# RP2350 register map
Vendor: Raspberry Pi; File version: 0.1
CPU: CM33 r1p0, little endian, MPU, FPU, VTOR, 4 interrupt priority bits, 54 interrupts, 8 SAU regions
Registers are 32-bit, read-write, reset 0x0 unless marked. A register's access mark holds for its fields unless they carry their own. Offsets are from the block's base; [hi:lo] are bit positions; 'fields as' and 'values as' point back to an identical list.

## XIP_QMI — QSPI Memory Interface. . Provides a memory-mapped interface to up to two SPI/DSPI/QSPI flash or PSRAM devices. Also provides a serial interface for programming and configuration of the external device.
Base 0x400D0000
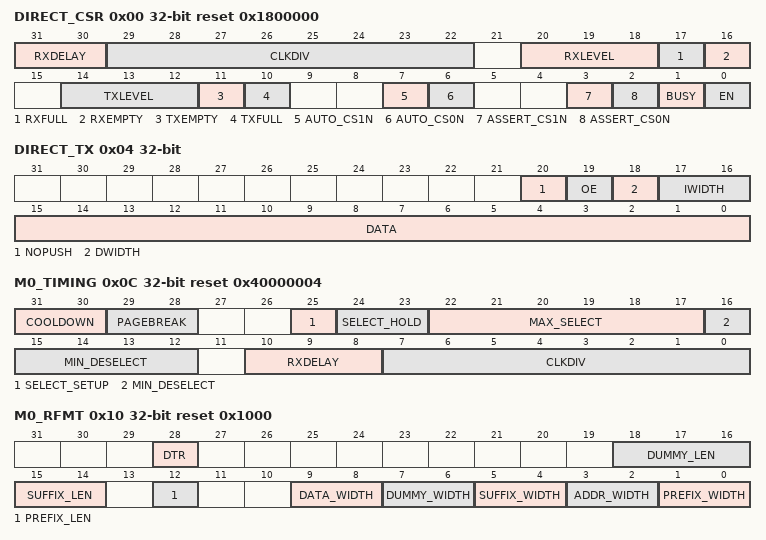
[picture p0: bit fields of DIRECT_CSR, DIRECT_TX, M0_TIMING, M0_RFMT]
0x00 DIRECT_CSR access per field reset 0x1800000 — Control and status for direct serial mode . Direct serial mode allows the processor to send and receive raw serial frames, for programming, configuration and control of the external memory devices. Only SPI mode 0 (CPOL=0 CPHA=0) is supported.
  [31:30] RXDELAY rw — Delay the read data sample timing, in units of one half of a system clock cycle. (Not necessarily half of an SCK cycle.)
  [29:22] CLKDIV rw — Clock divisor for direct serial mode. Divisors of 1..255 are encoded directly, and the maximum divisor of 256 is encoded by a value of CLKDIV=0. . The clock divisor can be changed on-the-fly by software, without halting or otherwise coordinating with the serial interface. The serial interface will sample the latest clock divisor each time it begins the transmission of a new byte.
  [20:18] RXLEVEL ro — Current level of DIRECT_RX FIFO
  [17] RXFULL ro — When 1, the DIRECT_RX FIFO is currently full. The serial interface will be stalled until data is popped; the interface will not begin a new serial frame when the DIRECT_TX FIFO is empty or the DIRECT_RX FIFO is full.
  [16] RXEMPTY ro — When 1, the DIRECT_RX FIFO is currently empty. If the processor attempts to read more data, the FIFO state is not affected, but the value returned to the processor is undefined.
  [14:12] TXLEVEL ro — Current level of DIRECT_TX FIFO
  [11] TXEMPTY ro — When 1, the DIRECT_TX FIFO is currently empty. Unless the processor pushes more data, transmission will stop and BUSY will go low once the current 8-bit serial frame completes.
  [10] TXFULL ro — When 1, the DIRECT_TX FIFO is currently full. If the processor tries to write more data, that data will be ignored.
  [7] AUTO_CS1N rw — When 1, automatically assert the CS1n chip select line whenever the BUSY flag is set.
  [6] AUTO_CS0N rw — When 1, automatically assert the CS0n chip select line whenever the BUSY flag is set.
  [3] ASSERT_CS1N rw — When 1, assert (i.e. drive low) the CS1n chip select line. . Note that this applies even when DIRECT_CSR_EN is 0.
  [2] ASSERT_CS0N rw — When 1, assert (i.e. drive low) the CS0n chip select line. . Note that this applies even when DIRECT_CSR_EN is 0.
  [1] BUSY ro — Direct mode busy flag. If 1, data is currently being shifted in/out (or would be if the interface were not stalled on the RX FIFO), and the chip select must not yet be deasserted. . The busy flag will also be set to 1 if a memory-mapped transfer is still in progress when direct mode is enabled. Direct mode blocks new memory-mapped transfers, but can't halt a transfer that is already in progress. If there is a chance that memory-mapped transfers may be in progress, the busy flag should be polled for 0 before asserting the chip select. (In practice you will usually discover this timing condition through other means, because any subsequent memory-mapped transfers when direct mode is enabled will return bus errors, which are difficult to ignore.)
  [0] EN rw — Enable direct mode. . In direct mode, software controls the chip select lines, and can perform direct SPI transfers by pushing data to the DIRECT_TX FIFO, and popping the same amount of data from the DIRECT_RX FIFO. . Memory-mapped accesses will generate bus errors when direct serial mode is enabled.
0x04 DIRECT_TX wo — Transmit FIFO for direct mode
  [20] NOPUSH read-has-side-effects — Inhibit the RX FIFO push that would correspond to this TX FIFO entry. . Useful to avoid garbage appearing in the RX FIFO when pushing the command at the beginning of a SPI transfer.
  [19] OE read-has-side-effects — Output enable (active-high). For single width (SPI), this field is ignored, and SD0 is always set to output, with SD1 always set to input. . For dual and quad width (DSPI/QSPI), this sets whether the relevant SDx pads are set to output whilst transferring this FIFO record. In this case the command/address should have OE set, and the data transfer should have OE set or clear depending on the direction of the transfer.
  [18] DWIDTH read-has-side-effects — Data width. If 0, hardware will transmit the 8 LSBs of the DIRECT_TX DATA field, and return an 8-bit value in the 8 LSBs of DIRECT_RX. If 1, the full 16-bit width is used. 8-bit and 16-bit transfers can be mixed freely.
  [17:16] IWIDTH read-has-side-effects — Configure whether this FIFO record is transferred with single/dual/quad interface width (0/1/2). Different widths can be mixed freely.
    0=S (Single width); 1=D (Dual width); 2=Q (Quad width)
  [15:0] DATA read-has-side-effects — Data pushed here will be clocked out falling edges of SCK (or before the very first rising edge of SCK, if this is the first pulse). For each byte clocked out, the interface will simultaneously sample one byte, on rising edges of SCK, and push this to the DIRECT_RX FIFO. . For 16-bit data, the least-significant byte is transmitted first.
0x08 DIRECT_RX ro — Receive FIFO for direct mode
  [15:0] DIRECT_RX read-has-side-effects — With each byte clocked out on the serial interface, one byte will simultaneously be clocked in, and will appear in this FIFO. The serial interface will stall when this FIFO is full, to avoid dropping data. . When 16-bit data is pushed into the TX FIFO, the corresponding RX FIFO push will also contain 16 bits of data. The least-significant byte is the first one received.
0x0C M0_TIMING reset 0x40000004 — Timing configuration register for memory address window 0.
  [31:30] COOLDOWN — Chip select cooldown period. When a memory transfer finishes, the chip select remains asserted for 64 x COOLDOWN system clock cycles, plus half an SCK clock period (rounded up for odd SCK divisors). After this cooldown expires, the chip select is always deasserted to save power. . If the next memory access arrives within the cooldown period, the QMI may be able to append more SCK cycles to the currently ongoing SPI transfer, rather than starting a new transfer. This reduces access latency and increases bus throughput. . Specifically, the next access must be in the same direction (read/write), access the same memory window (chip select 0/1), and follow sequentially the address of the last transfer. If any of these are false, the new access will first deassert the chip select, then begin a new transfer. . If COOLDOWN is 0, the address alignment configured by PAGEBREAK has been reached, or the total chip select assertion limit MAX_SELECT has been reached, the cooldown period is skipped, and the chip select will always be deasserted one half SCK period after the transfer finishes.
  [29:28] PAGEBREAK — When page break is enabled, chip select will automatically deassert when crossing certain power-of-2-aligned address boundaries. The next access will always begin a new read/write SPI burst, even if the address of the next access follows in sequence with the last access before the page boundary. . Some flash and PSRAM devices forbid crossing page boundaries with a single read/write transfer, or restrict the operating frequency for transfers that do cross page a boundary. This option allows the QMI to safely support those devices. . This field has no effect when COOLDOWN is disabled.
    0=NONE (No page boundary is enforced); 1=Break bursts crossing a 256-byte page boundary; 2=Break bursts crossing a 1024-byte quad-page boundary; 3=Break bursts crossing a 4096-byte sector boundary
  [25] SELECT_SETUP — Add up to one additional system clock cycle of setup between chip select assertion and the first rising edge of SCK. . The default setup time is one half SCK period, which is usually sufficient except for very high SCK frequencies with some flash devices.
  [24:23] SELECT_HOLD — Add up to three additional system clock cycles of active hold between the last falling edge of SCK and the deassertion of this window's chip select. . The default hold time is one system clock cycle. Note that flash datasheets usually give chip select active hold time from the last *rising* edge of SCK, and so even zero hold from the last falling edge would be safe. . Note that this is a minimum hold time guaranteed by the QMI: the actual chip select active hold may be slightly longer for read transfers with low clock divisors and/or high sample delays. Specifically, if the point two cycles after the last RX data sample is later than the last SCK falling edge, then the hold time is measured from *this* point. . Note also that, in case the final SCK pulse is masked to save energy (true for non-DTR reads when COOLDOWN is disabled or PAGE_BREAK is reached), all of QMI's timing logic behaves as though the clock pulse were still present. The SELECT_HOLD time is applied from the point where the last SCK falling edge would be if the clock pulse were not masked.
  [22:17] MAX_SELECT — Enforce a maximum assertion duration for this window's chip select, in units of 64 system clock cycles. If 0, the QMI is permitted to keep the chip select asserted indefinitely when servicing sequential memory accesses (see COOLDOWN). . This feature is required to meet timing constraints of PSRAM devices, which specify a maximum chip select assertion so they can perform DRAM refresh cycles. See also MIN_DESELECT, which can enforce a minimum deselect time. . If a memory access is in progress at the time MAX_SELECT is reached, the QMI will wait for the access to complete before deasserting the chip select. This additional time must be accounted for to calculate a safe MAX_SELECT value. In the worst case, this may be a fully-formed serial transfer, including command prefix and address, with a data payload as large as one cache line.
  [16:12] MIN_DESELECT — After this window's chip select is deasserted, it remains deasserted for half an SCK cycle (rounded up to an integer number of system clock cycles), plus MIN_DESELECT additional system clock cycles, before the QMI reasserts either chip select pin. . Nonzero values may be required for PSRAM devices which enforce a longer minimum CS deselect time, so that they can perform internal DRAM refresh cycles whilst deselected.
  [10:8] RXDELAY — Delay the read data sample timing, in units of one half of a system clock cycle. (Not necessarily half of an SCK cycle.) An RXDELAY of 0 means the sample is captured at the SDI input registers simultaneously with the rising edge of SCK launched from the SCK output register. . At higher SCK frequencies, RXDELAY may need to be increased to account for the round trip delay of the pads, and the clock-to-Q delay of the QSPI memory device.
  [7:0] CLKDIV — Clock divisor. Odd and even divisors are supported. Defines the SCK clock period in units of 1 system clock cycle. Divisors 1..255 are encoded directly, and a divisor of 256 is encoded with a value of CLKDIV=0. . The clock divisor can be changed on-the-fly, even when the QMI is currently accessing memory in this address window. All other parameters must only be changed when the QMI is idle. . If software is increasing CLKDIV in anticipation of an increase in the system clock frequency, a dummy access to either memory window (and appropriate processor barriers/fences) must be inserted after the Mx_TIMING write to ensure the SCK divisor change is in effect _before_ the system clock is changed.
0x10 M0_RFMT reset 0x1000 — Read transfer format configuration for memory address window 0. . Configure the bus width of each transfer phase individually, and configure the length or presence of the command prefix, command suffix and dummy/turnaround transfer phases. Only 24-bit addresses are supported. . The reset value of the M0_RFMT register is configured to support a basic 03h serial read transfer with no additional configuration.
  [28] DTR — Enable double transfer rate (DTR) for read commands: address, suffix and read data phases are active on both edges of SCK. SDO data is launched centre-aligned on each SCK edge, and SDI data is captured on the SCK edge that follows its launch. . DTR is implemented by halving the clock rate; SCK has a period of 2 x CLK_DIV throughout the transfer. The prefix and dummy phases are still single transfer rate. . If the suffix is quad-width, it must be 0 or 8 bits in length, to ensure an even number of SCK edges.
  [18:16] DUMMY_LEN — Length of dummy phase between command suffix and data phase, in units of 4 bits. (i.e. 1 cycle for quad width, 2 for dual, 4 for single)
    0=NONE (No dummy phase); 1=4 dummy bits; 2=8 dummy bits; 3=12 dummy bits; 4=16 dummy bits; 5=20 dummy bits; 6=24 dummy bits; 7=28 dummy bits
  [15:14] SUFFIX_LEN — Length of post-address command suffix, in units of 4 bits. (i.e. 1 cycle for quad width, 2 for dual, 4 for single) . Only values of 0 and 8 bits are supported.
    0=NONE (No suffix); 2=8-bit suffix
  [12] PREFIX_LEN — Length of command prefix, in units of 8 bits. (i.e. 2 cycles for quad width, 4 for dual, 8 for single)
    0=NONE (No prefix); 1=8-bit prefix
  [9:8] DATA_WIDTH — The width used for the data transfer
    0=S (Single width); 1=D (Dual width); 2=Q (Quad width)
  [7:6] DUMMY_WIDTH — The width used for the dummy phase, if any. . If width is single, SD0/MOSI is held asserted low during the dummy phase, and SD1...SD3 are tristated. If width is dual/quad, all IOs are tristated during the dummy phase.
    0=S (Single width); 1=D (Dual width); 2=Q (Quad width)
  [5:4] SUFFIX_WIDTH — The width used for the post-address command suffix, if any
    0=S (Single width); 1=D (Dual width); 2=Q (Quad width)
  [3:2] ADDR_WIDTH — The transfer width used for the address. The address phase always transfers 24 bits in total.
    0=S (Single width); 1=D (Dual width); 2=Q (Quad width)
  [1:0] PREFIX_WIDTH — The transfer width used for the command prefix, if any
    0=S (Single width); 1=D (Dual width); 2=Q (Quad width)
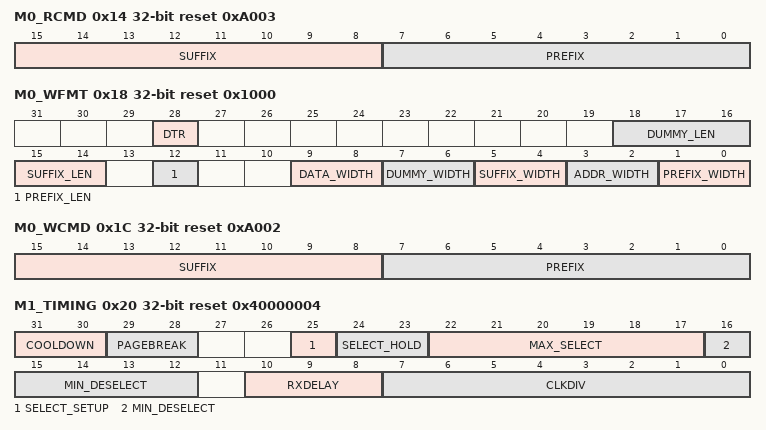
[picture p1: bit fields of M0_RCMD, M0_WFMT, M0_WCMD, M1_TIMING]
0x14 M0_RCMD reset 0xA003 — Command constants used for reads from memory address window 0. . The reset value of the M0_RCMD register is configured to support a basic 03h serial read transfer with no additional configuration.
  [15:8] SUFFIX — The command suffix bits following the address, if Mx_RFMT_SUFFIX_LEN is nonzero.
  [7:0] PREFIX — The command prefix bits to prepend on each new transfer, if Mx_RFMT_PREFIX_LEN is nonzero.
0x18 M0_WFMT reset 0x1000 — Write transfer format configuration for memory address window 0. . Configure the bus width of each transfer phase individually, and configure the length or presence of the command prefix, command suffix and dummy/turnaround transfer phases. Only 24-bit addresses are supported. . The reset value of the M0_WFMT register is configured to support a basic 02h serial write transfer. However, writes to this window must first be enabled via the XIP_CTRL_WRITABLE_M0 bit, as XIP memory is read-only by default.
  [28] DTR — Enable double transfer rate (DTR) for write commands: address, suffix and write data phases are active on both edges of SCK. SDO data is launched centre-aligned on each SCK edge, and SDI data is captured on the SCK edge that follows its launch. . DTR is implemented by halving the clock rate; SCK has a period of 2 x CLK_DIV throughout the transfer. The prefix and dummy phases are still single transfer rate. . If the suffix is quad-width, it must be 0 or 8 bits in length, to ensure an even number of SCK edges.
  [18:16] DUMMY_LEN — Length of dummy phase between command suffix and data phase, in units of 4 bits. (i.e. 1 cycle for quad width, 2 for dual, 4 for single)
    values as M0_RFMT.DUMMY_LEN
  [15:14] SUFFIX_LEN — Length of post-address command suffix, in units of 4 bits. (i.e. 1 cycle for quad width, 2 for dual, 4 for single) . Only values of 0 and 8 bits are supported.
    0=NONE (No suffix); 2=8-bit suffix
  [12] PREFIX_LEN — Length of command prefix, in units of 8 bits. (i.e. 2 cycles for quad width, 4 for dual, 8 for single)
    0=NONE (No prefix); 1=8-bit prefix
  [9:8] DATA_WIDTH — The width used for the data transfer
    0=S (Single width); 1=D (Dual width); 2=Q (Quad width)
  [7:6] DUMMY_WIDTH — The width used for the dummy phase, if any. . If width is single, SD0/MOSI is held asserted low during the dummy phase, and SD1...SD3 are tristated. If width is dual/quad, all IOs are tristated during the dummy phase.
    0=S (Single width); 1=D (Dual width); 2=Q (Quad width)
  [5:4] SUFFIX_WIDTH — The width used for the post-address command suffix, if any
    0=S (Single width); 1=D (Dual width); 2=Q (Quad width)
  [3:2] ADDR_WIDTH — The transfer width used for the address. The address phase always transfers 24 bits in total.
    0=S (Single width); 1=D (Dual width); 2=Q (Quad width)
  [1:0] PREFIX_WIDTH — The transfer width used for the command prefix, if any
    0=S (Single width); 1=D (Dual width); 2=Q (Quad width)
0x1C M0_WCMD reset 0xA002 — Command constants used for writes to memory address window 0. . The reset value of the M0_WCMD register is configured to support a basic 02h serial write transfer with no additional configuration.
  [15:8] SUFFIX — The command suffix bits following the address, if Mx_WFMT_SUFFIX_LEN is nonzero.
  [7:0] PREFIX — The command prefix bits to prepend on each new transfer, if Mx_WFMT_PREFIX_LEN is nonzero.
0x20 M1_TIMING reset 0x40000004 — Timing configuration register for memory address window 1.
  fields as M0_TIMING
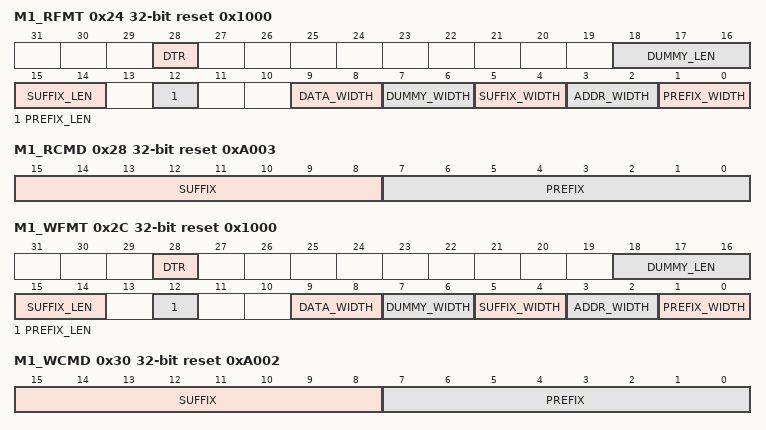
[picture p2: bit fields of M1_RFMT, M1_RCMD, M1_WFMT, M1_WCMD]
0x24 M1_RFMT reset 0x1000 — Read transfer format configuration for memory address window 1. . Configure the bus width of each transfer phase individually, and configure the length or presence of the command prefix, command suffix and dummy/turnaround transfer phases. Only 24-bit addresses are supported. . The reset value of the M1_RFMT register is configured to support a basic 03h serial read transfer with no additional configuration.
  fields as M0_RFMT
0x28 M1_RCMD reset 0xA003 — Command constants used for reads from memory address window 1. . The reset value of the M1_RCMD register is configured to support a basic 03h serial read transfer with no additional configuration.
  fields as M0_RCMD
0x2C M1_WFMT reset 0x1000 — Write transfer format configuration for memory address window 1. . Configure the bus width of each transfer phase individually, and configure the length or presence of the command prefix, command suffix and dummy/turnaround transfer phases. Only 24-bit addresses are supported. . The reset value of the M1_WFMT register is configured to support a basic 02h serial write transfer. However, writes to this window must first be enabled via the XIP_CTRL_WRITABLE_M1 bit, as XIP memory is read-only by default.
  fields as M0_WFMT
0x30 M1_WCMD reset 0xA002 — Command constants used for writes to memory address window 1. . The reset value of the M1_WCMD register is configured to support a basic 02h serial write transfer with no additional configuration.
  fields as M0_WCMD
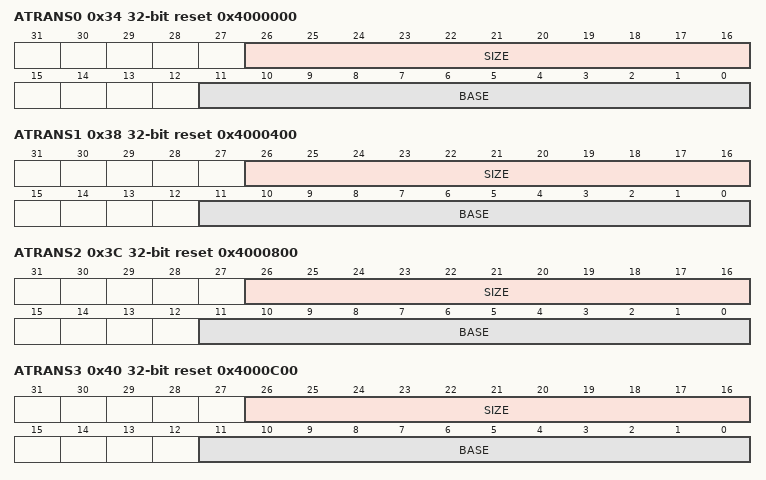
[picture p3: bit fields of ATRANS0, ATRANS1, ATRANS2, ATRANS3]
0x34 ATRANS0 reset 0x4000000 — Configure address translation for XIP virtual addresses 0x000000 through 0x3fffff (a 4 MiB window starting at +0 MiB). . Address translation allows a program image to be executed in place at multiple physical flash addresses (for example, a double-buffered flash image for over-the-air updates), without the overhead of position-independent code. . At reset, the address translation registers are initialised to an identity mapping, so that they can be ignored if address translation is not required. . Note that the XIP cache is fully virtually addressed, so a cache flush is required after changing the address translation.
  [26:16] SIZE — Translation aperture size for this virtual address range, in units of 4 kiB (one flash sector). . Bits 21:12 of the virtual address are compared to SIZE. Offsets greater than SIZE return a bus error, and do not cause a QSPI access.
  [11:0] BASE — Physical address base for this virtual address range, in units of 4 kiB (one flash sector). . Taking a 24-bit virtual address, firstly bits 23:22 (the two MSBs) are masked to zero, and then BASE is added to bits 23:12 (the upper 12 bits) to form the physical address. Translation wraps on a 16 MiB boundary.
0x38 ATRANS1 reset 0x4000400 — Configure address translation for XIP virtual addresses 0x400000 through 0x7fffff (a 4 MiB window starting at +4 MiB). . Address translation allows a program image to be executed in place at multiple physical flash addresses (for example, a double-buffered flash image for over-the-air updates), without the overhead of position-independent code. . At reset, the address translation registers are initialised to an identity mapping, so that they can be ignored if address translation is not required. . Note that the XIP cache is fully virtually addressed, so a cache flush is required after changing the address translation.
  fields as ATRANS0
0x3C ATRANS2 reset 0x4000800 — Configure address translation for XIP virtual addresses 0x800000 through 0xbfffff (a 4 MiB window starting at +8 MiB). . Address translation allows a program image to be executed in place at multiple physical flash addresses (for example, a double-buffered flash image for over-the-air updates), without the overhead of position-independent code. . At reset, the address translation registers are initialised to an identity mapping, so that they can be ignored if address translation is not required. . Note that the XIP cache is fully virtually addressed, so a cache flush is required after changing the address translation.
  fields as ATRANS0
0x40 ATRANS3 reset 0x4000C00 — Configure address translation for XIP virtual addresses 0xc00000 through 0xffffff (a 4 MiB window starting at +12 MiB). . Address translation allows a program image to be executed in place at multiple physical flash addresses (for example, a double-buffered flash image for over-the-air updates), without the overhead of position-independent code. . At reset, the address translation registers are initialised to an identity mapping, so that they can be ignored if address translation is not required. . Note that the XIP cache is fully virtually addressed, so a cache flush is required after changing the address translation.
  fields as ATRANS0
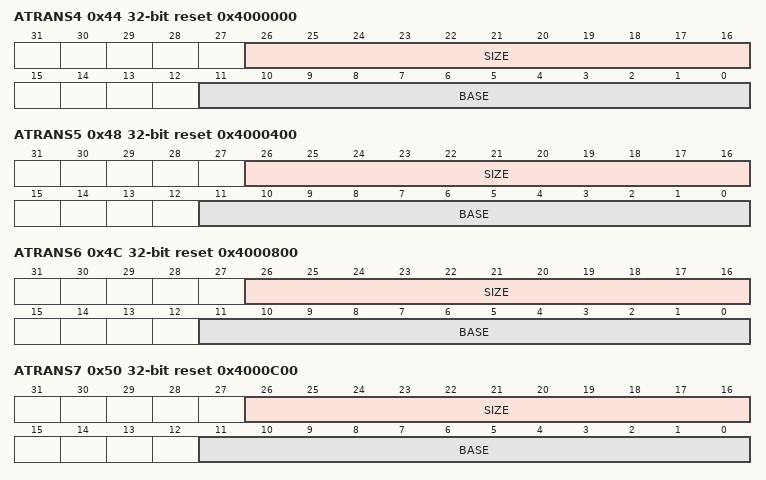
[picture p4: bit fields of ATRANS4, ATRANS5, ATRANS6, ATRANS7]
0x44 ATRANS4 reset 0x4000000 — Configure address translation for XIP virtual addresses 0x1000000 through 0x13fffff (a 4 MiB window starting at +16 MiB). . Address translation allows a program image to be executed in place at multiple physical flash addresses (for example, a double-buffered flash image for over-the-air updates), without the overhead of position-independent code. . At reset, the address translation registers are initialised to an identity mapping, so that they can be ignored if address translation is not required. . Note that the XIP cache is fully virtually addressed, so a cache flush is required after changing the address translation.
  fields as ATRANS0
0x48 ATRANS5 reset 0x4000400 — Configure address translation for XIP virtual addresses 0x1400000 through 0x17fffff (a 4 MiB window starting at +20 MiB). . Address translation allows a program image to be executed in place at multiple physical flash addresses (for example, a double-buffered flash image for over-the-air updates), without the overhead of position-independent code. . At reset, the address translation registers are initialised to an identity mapping, so that they can be ignored if address translation is not required. . Note that the XIP cache is fully virtually addressed, so a cache flush is required after changing the address translation.
  fields as ATRANS0
0x4C ATRANS6 reset 0x4000800 — Configure address translation for XIP virtual addresses 0x1800000 through 0x1bfffff (a 4 MiB window starting at +24 MiB). . Address translation allows a program image to be executed in place at multiple physical flash addresses (for example, a double-buffered flash image for over-the-air updates), without the overhead of position-independent code. . At reset, the address translation registers are initialised to an identity mapping, so that they can be ignored if address translation is not required. . Note that the XIP cache is fully virtually addressed, so a cache flush is required after changing the address translation.
  fields as ATRANS0
0x50 ATRANS7 reset 0x4000C00 — Configure address translation for XIP virtual addresses 0x1c00000 through 0x1ffffff (a 4 MiB window starting at +28 MiB). . Address translation allows a program image to be executed in place at multiple physical flash addresses (for example, a double-buffered flash image for over-the-air updates), without the overhead of position-independent code. . At reset, the address translation registers are initialised to an identity mapping, so that they can be ignored if address translation is not required. . Note that the XIP cache is fully virtually addressed, so a cache flush is required after changing the address translation.
  fields as ATRANS0
